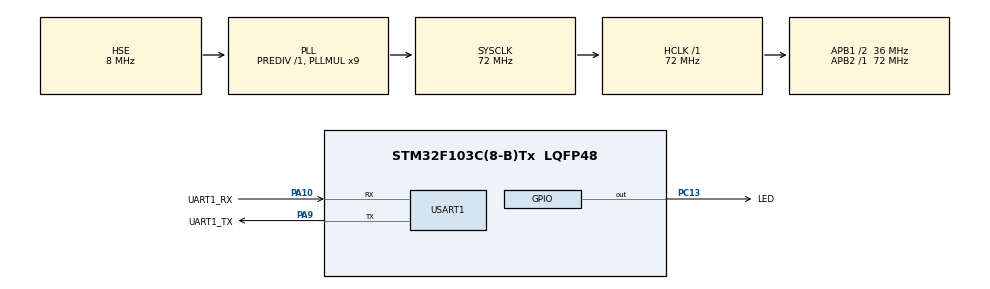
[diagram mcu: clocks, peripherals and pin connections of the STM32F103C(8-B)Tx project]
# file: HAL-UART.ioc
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Mcu.Family=STM32F1
Mcu.Name=STM32F103C(8-B)Tx
Mcu.Package=LQFP48
NVIC.PriorityGroup=NVIC_PRIORITYGROUP_4
NVIC.USART1_IRQn=true\:0\:0\:false\:false\:true\:true\:true\:true
PA10.GPIO_Label=UART1_RX
PA10.Mode=Asynchronous
PA10.Signal=USART1_RX
PA13.Mode=Serial_Wire
PA13.Signal=SYS_JTMS-SWDIO
PA14.Mode=Serial_Wire
PA14.Signal=SYS_JTCK-SWCLK
PA9.GPIO_Label=UART1_TX
PA9.Mode=Asynchronous
PA9.Signal=USART1_TX
PC13-TAMPER-RTC.GPIO_Label=LED
PC13-TAMPER-RTC.Signal=GPIO_Output
PD0-OSC_IN.Mode=HSE-External-Oscillator
PD0-OSC_IN.Signal=RCC_OSC_IN
PD1-OSC_OUT.Mode=HSE-External-Oscillator
PD1-OSC_OUT.Signal=RCC_OSC_OUT
ProjectManager.HeapSize=0x200
ProjectManager.StackSize=0x400
ProjectManager.TargetToolchain=MDK-ARM V5.32
RCC.AHBFreq_Value=72000000
RCC.APB1CLKDivider=RCC_HCLK_DIV2
RCC.APB1Freq_Value=36000000
RCC.APB1TimFreq_Value=72000000
RCC.APB2Freq_Value=72000000
RCC.APB2TimFreq_Value=72000000
RCC.HCLKFreq_Value=72000000
RCC.PLLMUL=RCC_PLL_MUL9
RCC.PLLSourceVirtual=RCC_PLLSOURCE_HSE
RCC.SYSCLKFreq_VALUE=72000000
RCC.SYSCLKSource=RCC_SYSCLKSOURCE_PLLCLK
RCC.USBFreq_Value=72000000
USART1.VirtualMode=VM_ASYNC
board=custom

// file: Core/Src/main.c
/* USER CODE BEGIN Header */
/**
 ******************************************************************************
 * @file           : main.c
 * @brief          : Main program body
 ******************************************************************************
 * @attention
 *
 * Copyright (c) 2022 STMicroelectronics.
 * All rights reserved.
 *
 * This software is licensed under terms that can be found in the LICENSE file
 * in the root directory of this software component.
 * If no LICENSE file comes with this software, it is provided AS-IS.
 *
 ******************************************************************************
 */
/* USER CODE END Header */
#include "main.h"
#include "usart.h"
#include "gpio.h"
#include "ADS1256.h"
#include "delay.h"
#include "oled.h"

/* USER CODE BEGIN Includes */
#include <stdio.h> //用到了printf函数
/* USER CODE END Includes */

void SystemClock_Config(void);

/* USER CODE BEGIN 0 */
/* save data from UART receive interrupt*/
#define UART1_REC_LEN 200				// 定义最大接收字节数 200
uint8_t UART1_RX_Buffer[UART1_REC_LEN]; // 接受缓存 最大为UART1_REC_LEN个字节
uint16_t UART1_RX_STA = 0;				// 接收状态标记
// 接收状态
// bit15置1 0x8000 接收到0x0a 即\n转移符 表示接收完成
// bit14置1 0x4000 接收到0x0d 即\r转义符
// bit13~0 表示可以接受到的数据个数最大为 2^13

uint8_t Res = 0; // 保存接受到的1BYTE数据
uint32_t data_in0;
uint32_t data_in1;
uint32_t data_in2;
uint32_t data_in3;
uint32_t data_in4;
uint32_t data_in5;
uint32_t data_in6;
uint32_t data_in7;
double v0;
double v1;
double v2;
double v3;
double v4;
double v5;
double v6;
double v7;

/*printf函数重定义，使用用UART1打印到上位机*/

int fputc(int ch, FILE *f)
{
	unsigned char temp[1] = {ch};
	HAL_UART_Transmit(&huart1, temp, 1, 0xffff); // 循环发送,直到发送完毕
	return ch;
}

/* USER CODE END 0 */

int main(void)
{

	/* MCU Configuration--------------------------------------------------------*/

	/* Reset of all peripherals, Initializes the Flash interface and the Systick. */
	HAL_Init();

	/* Configure the system clock */
	SystemClock_Config();

	/* Initialize all configured peripherals */
	MX_GPIO_Init();
	MX_USART1_UART_Init();
	/* USER CODE BEGIN 2 */
	HAL_UART_Receive_IT(&huart1, &Res, 1); // 将Res作为UART中断接收数据的变量
	HAL_GPIO_WritePin(LED_GPIO_Port, LED_Pin, GPIO_PIN_RESET);
	Delay_Init();
	ADS1256_Init(ADS1256_GAIN_1, ADS1256_DRATE_500SPS);
	Delay_ms(100);

	//	OLED_Init();
	//	OLED_DisPlay_On();
	//	OLED_ShowNum(20,20,852,4,12,1);
	/* USER CODE END 2 */

	/* Infinite loop */
	while (1)
	{

		/* USER CODE BEGIN 3 */
		if (UART1_RX_STA & 0x8000) // 判断UART接收是否完成
		{
			/* printf("Get data:");
			HAL_UART_Transmit(&huart1, UART1_RX_Buffer, UART1_RX_STA & 0x3fff, 0xffff); // 正常发送，非中断发送
			while (huart1.gState != HAL_UART_STATE_READY)
				; // 等待发送完成MCU->上位机
			printf("\r\n"); */
			if (UART1_RX_Buffer[0] == '0')
			{
				data_in0 = ADS1256ReadData(ADS1256_MUXP_AIN0, ADS1256_MUXN_AINCOM);
				printf("%d\r\n",data_in0);
			}
			else if (UART1_RX_Buffer[0] == '1')
			{
				data_in1 = ADS1256ReadData(ADS1256_MUXP_AIN1, ADS1256_MUXN_AINCOM);
				printf("%d\r\n",data_in1);
			}
			else if (UART1_RX_Buffer[0] == '2')
			{
				data_in2 = ADS1256ReadData(ADS1256_MUXP_AIN2, ADS1256_MUXN_AINCOM);
				printf("%d\r\n",data_in2);
			}
			else if (UART1_RX_Buffer[0] == '3')
			{
				data_in3 = ADS1256ReadData(ADS1256_MUXP_AIN3, ADS1256_MUXN_AINCOM);
				printf("%d\r\n",data_in3);
			}
			else if (UART1_RX_Buffer[0] == '4')
			{
				data_in4 = ADS1256ReadData(ADS1256_MUXP_AIN4, ADS1256_MUXN_AINCOM);
				printf("%d\r\n",data_in4);
			}
			else if (UART1_RX_Buffer[0] == '5')
			{
				data_in5 = ADS1256ReadData(ADS1256_MUXP_AIN5, ADS1256_MUXN_AINCOM);
				printf("%d\r\n",data_in5);
			}
			else if (UART1_RX_Buffer[0] == '6')
			{
				data_in6 = ADS1256ReadData(ADS1256_MUXP_AIN6, ADS1256_MUXN_AINCOM);
				printf("%d\r\n",data_in6);
			}
			else if (UART1_RX_Buffer[0] == '7')
			{
				data_in7 = ADS1256ReadData(ADS1256_MUXP_AIN7, ADS1256_MUXN_AINCOM);
				printf("%d\r\n",data_in7);
			}

			UART1_RX_STA = 0;
		}
		/* HAL_GPIO_TogglePin(LED_GPIO_Port, LED_Pin);
		printf("test\r\n");
		ADS1256_Init(ADS1256_GAIN_1, ADS1256_DRATE_30000SPS);
		Delay_ms(100);
		data_in0 = ADS1256ReadData(ADS1256_MUXP_AIN0, ADS1256_MUXN_AINCOM);
		Delay_ms(100);
		data_in1 = ADS1256ReadData(ADS1256_MUXP_AIN1, ADS1256_MUXN_AINCOM);
		Delay_ms(100);
		data_in2 = ADS1256ReadData(ADS1256_MUXP_AIN2, ADS1256_MUXN_AINCOM);
		Delay_ms(100);
		data_in3 = ADS1256ReadData(ADS1256_MUXP_AIN3, ADS1256_MUXN_AINCOM);
		Delay_ms(100);
		data_in4 = ADS1256ReadData(ADS1256_MUXP_AIN4, ADS1256_MUXN_AINCOM);
		Delay_ms(100);
		data_in5 = ADS1256ReadData(ADS1256_MUXP_AIN5, ADS1256_MUXN_AINCOM);
		Delay_ms(100);
		data_in6 = ADS1256ReadData(ADS1256_MUXP_AIN6, ADS1256_MUXN_AINCOM);
		Delay_ms(100);
		data_in7 = ADS1256ReadData(ADS1256_MUXP_AIN7, ADS1256_MUXN_AINCOM);
		Delay_ms(100);
		v0 = ADS1256GetVolt(ADS1256_MUXP_AIN0, ADS1256_MUXN_AINCOM, ADS1256_GAIN_1);
		Delay_ms(100);
		v1 = ADS1256GetVolt(ADS1256_MUXP_AIN1, ADS1256_MUXN_AINCOM, ADS1256_GAIN_1);
		Delay_ms(100);
		v2 = ADS1256GetVolt(ADS1256_MUXP_AIN2, ADS1256_MUXN_AINCOM, ADS1256_GAIN_1);
		Delay_ms(100);
		v3 = ADS1256GetVolt(ADS1256_MUXP_AIN3, ADS1256_MUXN_AINCOM, ADS1256_GAIN_1);
		Delay_ms(100);
		v4 = ADS1256GetVolt(ADS1256_MUXP_AIN4, ADS1256_MUXN_AINCOM, ADS1256_GAIN_1);
		Delay_ms(100);
		v5 = ADS1256GetVolt(ADS1256_MUXP_AIN5, ADS1256_MUXN_AINCOM, ADS1256_GAIN_1);
		Delay_ms(100);
		v6 = ADS1256GetVolt(ADS1256_MUXP_AIN6, ADS1256_MUXN_AINCOM, ADS1256_GAIN_1);
		Delay_ms(100);
		v7 = ADS1256GetVolt(ADS1256_MUXP_AIN7, ADS1256_MUXN_AINCOM, ADS1256_GAIN_1);
		printf("AIN0=%d", data_in0);
		printf("\r\n");
		printf("AIN1=%d", data_in1);
		printf("\r\n");
		printf("AIN2=%d", data_in2);
		printf("\r\n");
		printf("AIN3=%d", data_in3);
		printf("\r\n");
		printf("AIN4=%d", data_in4);
		printf("\r\n");
		printf("AIN5=%d", data_in5);
		printf("\r\n");
		printf("AIN6=%d", data_in6);
		printf("\r\n");
		printf("AIN7=%d", data_in7);
		printf("\r\n");
		printf("V0=%f", v0);
		printf("\r\n");
		printf("V1=%f", v1);
		printf("\r\n");
		printf("V2=%f", v2);
		printf("\r\n");
		printf("V3=%f", v3);
		printf("\r\n");
		printf("V4=%f", v4);
		printf("\r\n");
		printf("V5=%f", v5);
		printf("\r\n");
		printf("V6=%f", v6);
		printf("\r\n");
		printf("V7=%f", v7);
		printf("\r\n");
		printf("\r\n");
		Delay_ms(1500); */
	}
	/* USER CODE END 3 */
}

void SystemClock_Config(void)
{
	RCC_OscInitTypeDef RCC_OscInitStruct = {0};
	RCC_ClkInitTypeDef RCC_ClkInitStruct = {0};

	/** Initializes the RCC Oscillators according to the specified parameters
	 * in the RCC_OscInitTypeDef structure.
	 */
	RCC_OscInitStruct.OscillatorType = RCC_OSCILLATORTYPE_HSE;
	RCC_OscInitStruct.HSEState = RCC_HSE_ON;
	RCC_OscInitStruct.HSEPredivValue = RCC_HSE_PREDIV_DIV1;
	RCC_OscInitStruct.HSIState = RCC_HSI_ON;
	RCC_OscInitStruct.PLL.PLLState = RCC_PLL_ON;
	RCC_OscInitStruct.PLL.PLLSource = RCC_PLLSOURCE_HSE;
	RCC_OscInitStruct.PLL.PLLMUL = RCC_PLL_MUL9;
	if (HAL_RCC_OscConfig(&RCC_OscInitStruct) != HAL_OK)
	{
		Error_Handler();
	}

	/** Initializes the CPU, AHB and APB buses clocks
	 */
	RCC_ClkInitStruct.ClockType = RCC_CLOCKTYPE_HCLK | RCC_CLOCKTYPE_SYSCLK | RCC_CLOCKTYPE_PCLK1 | RCC_CLOCKTYPE_PCLK2;
	RCC_ClkInitStruct.SYSCLKSource = RCC_SYSCLKSOURCE_PLLCLK;
	RCC_ClkInitStruct.AHBCLKDivider = RCC_SYSCLK_DIV1;
	RCC_ClkInitStruct.APB1CLKDivider = RCC_HCLK_DIV2;
	RCC_ClkInitStruct.APB2CLKDivider = RCC_HCLK_DIV1;

	if (HAL_RCC_ClockConfig(&RCC_ClkInitStruct, FLASH_LATENCY_2) != HAL_OK)
	{
		Error_Handler();
	}
}

/* USER CODE BEGIN 4 */
void HAL_UART_RxCpltCallback(UART_HandleTypeDef *huart) // 自定义回调函数 在UART_Receive_IT()中调用
{
	// 判断是哪个串口触发的中断  huart1.Instance = USART1;定义在MX_USART1_UART_Init中
	if (huart == &huart1) // huart ->Instance == USART1两种判断条件等价
	{
		if(Res != 0x00)
		{
			if ((UART1_RX_STA & 0x8000) == 0) // 接收未完成&位运算符 &&短路与判断
			{
				if (UART1_RX_STA & 0x4000) // 接收到 \r
				{
					if (Res == 0x0a) // 下一个必须是接收 \n
					UART1_RX_STA |= 0x8000;
					else
						UART1_RX_STA = 0;
				}
				else // 未接收到\r
				{
					if (Res == 0x0d) // Receive \r
					{
						UART1_RX_STA |= 0x4000;
					}
					else
					{
						UART1_RX_Buffer[UART1_RX_STA & 0X3FFF] = Res;
						UART1_RX_STA++;
						if (UART1_RX_STA > UART1_REC_LEN - 1)
							UART1_RX_STA = 0; // 如果接收数据大于200Byte 重新开始接收
					}
				}
			}
		}
		HAL_UART_Receive_IT(&huart1, &Res, 1); // 完成一次接受，再此开启中断
	}
}
/* USER CODE END 4 */

void Error_Handler(void)
{
	__disable_irq();
	while (1)
	{
	}
}
